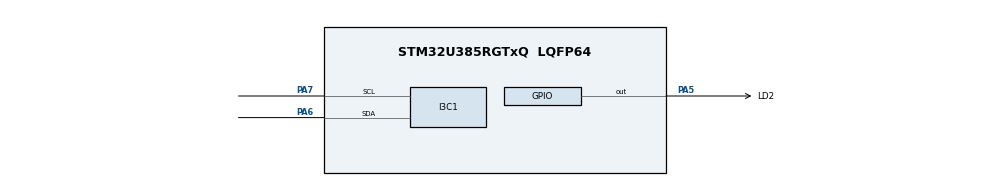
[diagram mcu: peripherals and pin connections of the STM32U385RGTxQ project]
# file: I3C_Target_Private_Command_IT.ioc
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CORTEX_M33_NS.userName=CORTEX_M33
I3C1.Identifier=0xC6
I3C1.MIPIIdentifier=DEVICE_ID
I3C1.Register1=0x0000005e
I3C1.hexBusAvailableDuration=0x5e
Mcu.Family=STM32U3
Mcu.Name=STM32U385RGTxQ
Mcu.Package=LQFP64
Mcu.UserConstants=DEVICE_ID,0x01
NVIC.I3C1_ER_IRQn=true\:0\:0\:false\:false\:true\:true\:true\:true
NVIC.I3C1_EV_IRQn=true\:0\:0\:false\:false\:true\:true\:true\:true
NVIC.PriorityGroup=NVIC_PRIORITYGROUP_4
PA5.GPIO_Label=LD2
PA5.Signal=GPIO_Output
PA6.Mode=Target
PA6.Signal=I3C1_SDA
PA7.Mode=Target
PA7.Signal=I3C1_SCL
ProjectManager.HeapSize=0x200
ProjectManager.StackSize=0x400
ProjectManager.TargetToolchain=EWARM V9.20
RCC.ADCFreq_Value=96000000
RCC.AHBFreq_Value=96000000
RCC.APB1Freq_Value=96000000
RCC.APB1TimFreq_Value=96000000
RCC.APB2Freq_Value=96000000
RCC.APB2TimFreq_Value=96000000
RCC.APB3Freq_Value=96000000
RCC.CortexFreq_Value=12000000
RCC.HCLKFreq_Value=96000000
RCC.HSE_VALUE=16000000
RCC.HSI48_VALUE=48000000
RCC.HSI_VALUE=16000000
RCC.LSE_VALUE=32768
RCC.LSIDIV_VALUE=32000
RCC.MSISDIV=RCC_MSI_DIV1
RCC.SYSCLKFreq_VALUE=96000000
RCC.USBFreq_Value=96000000
VP_ICACHE_VS_ICACHE.Mode=DirectMappedCache
VP_PWR_VS_DBSignals.Mode=DisableDeadBatterySignals
VP_PWR_VS_LPOM.Mode=PowerOptimisation
VP_PWR_VS_SECSignals.Mode=Security/Privilege
board=custom

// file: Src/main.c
/* USER CODE BEGIN Header */
/**
  ******************************************************************************
  * @file    I3C/I3C_Target_Private_Command_IT/Src/main.c
  * @author  MCD Application Team
  * @brief   This sample code shows how to use STM32U3xx I3C LL API as Target
  *          to receive and transmit a data buffer
  *          with a communication process based on Interrupt transfer.
  *          The communication is done using 2 Boards.
  ******************************************************************************
  * @attention
  *
  * Copyright (c) 2024 STMicroelectronics.
  * All rights reserved.
  *
  * This software is licensed under terms that can be found in the LICENSE file
  * in the root directory of this software component.
  * If no LICENSE file comes with this software, it is provided AS-IS.
  *
  ******************************************************************************
  */
/* USER CODE END Header */
#include "main.h"

/* USER CODE BEGIN PV */
/* Buffer used for transmission */
uint8_t aTxBuffer[] = " ****I3C_TwoBoards communication based on IT****  ****I3C_TwoBoards communication based on IT****  ****I3C_TwoBoards communication based on IT**** ";
/* Buffer used for reception */
uint8_t aRxBuffer[RXBUFFERSIZE];
/* Buffer used for reception */
__IO uint8_t ubNbRxData = 0;
/* Buffer used for transmission */
__IO uint8_t ubNbTxData = 0;
/* Completion status */
__IO uint8_t ubFrameComplete = 0;
/* USER CODE END PV */

void SystemClock_Config(void);
static void MX_GPIO_Init(void);
static void MX_I3C1_Init(void);
static void MX_ICACHE_Init(void);
/* USER CODE BEGIN PFP */
void LED_On(void);
void LED_Off(void);
void LED_Toggle(void);
void LED_Blinking(uint32_t Period);
void FlushBuffer8(uint8_t* pBuffer1, uint16_t BufferSize);
static uint16_t Buffercmp(uint8_t *pBuffer1, uint8_t *pBuffer2, uint16_t BufferLength);
/* USER CODE END PFP */

int main(void)
{

  /* MCU Configuration--------------------------------------------------------*/

  /* Reset of all peripherals, Initializes the Flash interface and the Systick. */

  /* System interrupt init*/
  NVIC_SetPriorityGrouping(NVIC_PRIORITYGROUP_4);

  /* SysTick_IRQn interrupt configuration */
  NVIC_SetPriority(SysTick_IRQn, NVIC_EncodePriority(NVIC_GetPriorityGrouping(),15, 0));

  /* Configure the system clock */
  SystemClock_Config();

  /* Initialize all configured peripherals */
  MX_GPIO_Init();
  MX_I3C1_Init();
  MX_ICACHE_Init();
  /* USER CODE BEGIN 2 */
  /* Set LD2 Off */
  LED_Off();
  /* Set Preload information */
  LL_I3C_ConfigTxPreload(I3C1, TXBUFFERSIZE);
  /* Wait end of Private transfer procedure */
  while(ubFrameComplete != 2);
  /*##- Compare the sent and received buffers ############################*/
  if (Buffercmp((uint8_t *)aTxBuffer, (uint8_t *)aRxBuffer, RXBUFFERSIZE))
  {
    /* Processing Error */
    Error_Handler();
  }
  else
  {
    /* LD2 On */
    LED_On();
  }
  /* USER CODE END 2 */

  /* Infinite loop */
  while (1)
  {

  }
}

void SystemClock_Config(void)
{
  /** Enable Epod Booster
  */
  LL_AHB1_GRP2_EnableClock(LL_AHB1_GRP2_PERIPH_PWR);
  LL_RCC_SetEPODBoosterClkSource(LL_RCC_EPODBOOSTCLKSRCE_MSIS);
  LL_RCC_SetEPODBoosterClkPrescaler(LL_RCC_EPODBOOSTCLKPRESCAL_1);
  LL_PWR_EnableEPODBooster();
  while(LL_PWR_IsActiveFlag_BOOST() != 1U)
  {
  }

  /** Configure the main internal regulator output voltage
  */
  LL_PWR_SetRegulVoltageScaling(LL_PWR_REGU_VOLTAGE_SCALE1);
  while(LL_PWR_GetRegulCurrentVOS() != LL_PWR_REGU_VOLTAGE_SCALE1)
  {
  }

  /** Set Flash latency before switching to MSIS
  */
  LL_FLASH_SetLatency(LL_FLASH_LATENCY_2);
  while(LL_FLASH_GetLatency() != LL_FLASH_LATENCY_2)
  {
  }

  /** Activate MSIS as source
  */
  LL_RCC_MSIS_SetClockSource(LL_RCC_MSIS_CLOCK_SOURCE_RC0);
  LL_RCC_MSIS_SetClockDivision(LL_RCC_MSIS_CLOCK_SOURCE_RC_DIV_1);
  LL_RCC_MSI_SetMSIxClockRange();
  LL_RCC_SetSysClkSource(LL_RCC_SYS_CLKSOURCE_MSIS);

  /** Wait till System clock is ready
  */
  while(LL_RCC_GetSysClkSource() != LL_RCC_SYS_CLKSOURCE_MSIS)
  {
  }

  LL_RCC_SetAHBPrescaler(LL_RCC_HCLK_SYSCLK_DIV_1);
  LL_RCC_SetAPB1Prescaler(LL_RCC_APB1_HCLK_DIV_1);
  LL_RCC_SetAPB2Prescaler(LL_RCC_APB2_HCLK_DIV_1);
  LL_RCC_SetAPB3Prescaler(LL_RCC_APB3_HCLK_DIV_1);

  LL_Init1msTick(96000000);

  LL_SetSystemCoreClock(96000000);
}

static void MX_I3C1_Init(void)
{

  LL_GPIO_InitTypeDef GPIO_InitStruct = {0};

  LL_RCC_SetI3CClockSource(LL_RCC_I3C1_CLKSOURCE_PCLK1);

  /* Peripheral clock enable */
  LL_APB1_GRP1_EnableClock(LL_APB1_GRP1_PERIPH_I3C1);

  LL_AHB2_GRP1_EnableClock(LL_AHB2_GRP1_PERIPH_GPIOA);
  /**I3C1 GPIO Configuration
  PA6   ------> I3C1_SDA
  PA7   ------> I3C1_SCL
  */
  GPIO_InitStruct.Pin = LL_GPIO_PIN_6|LL_GPIO_PIN_7;
  GPIO_InitStruct.Mode = LL_GPIO_MODE_ALTERNATE;
  GPIO_InitStruct.Speed = LL_GPIO_SPEED_FREQ_VERY_HIGH;
  GPIO_InitStruct.OutputType = LL_GPIO_OUTPUT_PUSHPULL;
  GPIO_InitStruct.Pull = LL_GPIO_PULL_NO;
  GPIO_InitStruct.Alternate = LL_GPIO_AF_6;
  LL_GPIO_Init(GPIOA, &GPIO_InitStruct);

  /* I3C1 interrupt Init */
  NVIC_SetPriority(I3C1_EV_IRQn, NVIC_EncodePriority(NVIC_GetPriorityGrouping(),0, 0));
  NVIC_EnableIRQ(I3C1_EV_IRQn);
  NVIC_SetPriority(I3C1_ER_IRQn, NVIC_EncodePriority(NVIC_GetPriorityGrouping(),0, 0));
  NVIC_EnableIRQ(I3C1_ER_IRQn);

  /** I3C Initialization
  */
  LL_I3C_SetMode(I3C1, LL_I3C_MODE_TARGET);
  LL_I3C_SetAvalTiming(I3C1, 0x0000005e);

  /** Configure FIFO
  */
  LL_I3C_SetRxFIFOThreshold(I3C1, LL_I3C_RXFIFO_THRESHOLD_1_4);
  LL_I3C_SetTxFIFOThreshold(I3C1, LL_I3C_TXFIFO_THRESHOLD_1_4);
  LL_I3C_DisableControlFIFO(I3C1);
  LL_I3C_DisableStatusFIFO(I3C1);

  /** Configure Target
  */
  LL_I3C_SetDeviceCharacteristics(I3C1, 0xC6);
  LL_I3C_SetMIPIInstanceID(I3C1, DEVICE_ID);
  LL_I3C_DisableControllerRoleReq(I3C1);
  LL_I3C_DisableHotJoin(I3C1);
  LL_I3C_DisableIBI(I3C1);
  LL_I3C_SetDeviceIBIPayload(I3C1, LL_I3C_IBI_NO_ADDITIONAL_DATA);
  LL_I3C_ConfigNbIBIAddData(I3C1, LL_I3C_PAYLOAD_1_BYTE);
  LL_I3C_SetMaxReadLength(I3C1, 0);
  LL_I3C_SetMaxWriteLength(I3C1, 0);
  LL_I3C_SetDeviceCapabilityOnBus(I3C1, LL_I3C_DEVICE_ROLE_AS_TARGET);
  LL_I3C_SetGrpAddrHandoffSupport(I3C1, LL_I3C_HANDOFF_GRP_ADDR_NOT_SUPPORTED);
  LL_I3C_SetDataTurnAroundTime(I3C1, LL_I3C_TURNAROUND_TIME_TSCO_LESS_12NS);
  LL_I3C_SetMiddleByteTurnAround(I3C1, 0);
  LL_I3C_SetDataSpeedLimitation(I3C1, LL_I3C_NO_DATA_SPEED_LIMITATION);
  LL_I3C_SetMaxDataSpeedFormat(I3C1, LL_I3C_GETMXDS_FORMAT_1);
  LL_I3C_SetHandoffActivityState(I3C1, LL_I3C_HANDOFF_ACTIVITY_STATE_0);
  LL_I3C_SetControllerHandoffDelayed(I3C1, LL_I3C_HANDOFF_NOT_DELAYED);
  LL_I3C_SetPendingReadMDB(I3C1, LL_I3C_MDB_NO_PENDING_READ_NOTIFICATION);

  /** Enable the selected I3C peripheral
  */
  LL_I3C_Enable(I3C1);
  /* USER CODE BEGIN I3C1_Init 2 */
  LL_I3C_EnableIT_DAUPD(I3C1);
  LL_I3C_EnableIT_FC(I3C1);
  LL_I3C_EnableIT_RXFNE(I3C1);
  LL_I3C_EnableIT_TXFNF(I3C1);
  LL_I3C_EnableIT_ERR(I3C1);
  /* USER CODE END I3C1_Init 2 */

}

static void MX_ICACHE_Init(void)
{

  /** Enable instruction cache in 1-way (direct mapped cache)
  */
  LL_ICACHE_SetMode(LL_ICACHE_1WAY);
  LL_ICACHE_Enable();

}

static void MX_GPIO_Init(void)
{
  LL_GPIO_InitTypeDef GPIO_InitStruct = {0};

  /* GPIO Ports Clock Enable */
  LL_AHB2_GRP1_EnableClock(LL_AHB2_GRP1_PERIPH_GPIOA);

  /**/
  LL_GPIO_ResetOutputPin(LD2_GPIO_Port, LD2_Pin);

  /**/
  GPIO_InitStruct.Pin = LD2_Pin;
  GPIO_InitStruct.Mode = LL_GPIO_MODE_OUTPUT;
  GPIO_InitStruct.Speed = LL_GPIO_SPEED_FREQ_LOW;
  GPIO_InitStruct.OutputType = LL_GPIO_OUTPUT_PUSHPULL;
  GPIO_InitStruct.Pull = LL_GPIO_PULL_NO;
  LL_GPIO_Init(LD2_GPIO_Port, &GPIO_InitStruct);

}

/* USER CODE BEGIN 4 */
/**
  * @brief  Flush 8-bit buffer.
  * @param  pBuffer1: pointer to the buffer to be flushed.
  * @param  BufferSize: Size of Buffer.
  * @retval None
  */
void FlushBuffer8(uint8_t* pBuffer1, uint16_t BufferSize)
{
  uint8_t Index = 0;
  for (Index = 0; Index < BufferSize; Index++)
  {
    pBuffer1[Index] = 0;
  }
}
/**
  * @brief  Turn-on LD2.
  * @param  None
  * @retval None
  */
void LED_On(void)
{
  /* Turn LD2 on */
  LL_GPIO_SetOutputPin(LD2_GPIO_Port, LD2_Pin);
}
/**
  * @brief  Turn-off LD2.
  * @param  None
  * @retval None
  */
void LED_Off(void)
{
  /* Turn LD2 off */
  LL_GPIO_ResetOutputPin(LD2_GPIO_Port, LD2_Pin);
}
/**
  * @brief  Toggle LD2.
  * @param  None
  * @retval None
  */
void LED_Toggle(void)
{
  /* Toggle LD2 on */
  LL_GPIO_TogglePin(LD2_GPIO_Port, LD2_Pin);
}
/**
  * @brief  Set LD2 to Blinking mode for an infinite loop (toggle period based on value provided as input parameter).
  * @param  Period : Period of time (in ms) between each toggling of LED
  *   This parameter can be user defined values. Pre-defined values used in that example are :
  *     @arg LED_BLINK_FAST : Fast Blinking
  *     @arg LED_BLINK_SLOW : Slow Blinking
  *     @arg LED_BLINK_ERROR : Error specific Blinking
  * @retval None
  */
void LED_Blinking(uint32_t Period)
{
  /* Turn LD2 on */
  LED_On();
  /* Toggle IO in an infinite loop */
  while (1)
  {
    LED_Toggle();
    LL_mDelay(Period);
  }
}
/**
  * @brief  Compares two buffers.
  * @param  pBuffer1, pBuffer2: buffers to be compared.
  * @param  BufferLength: buffer's length
  * @retval 0  : pBuffer1 identical to pBuffer2
  *         >0 : pBuffer1 differs from pBuffer2
  */
static uint16_t Buffercmp(uint8_t *pBuffer1, uint8_t *pBuffer2, uint16_t BufferLength)
{
  while (BufferLength--)
  {
    if ((*pBuffer1) != *pBuffer2)
    {
      return BufferLength;
    }
    pBuffer1++;
    pBuffer2++;
  }
  return 0;
}
/******************************************************************************/
/*   IRQ HANDLER TREATMENT Functions                                          */
/******************************************************************************/
/**
  * @brief  Target Event treatment callback.
  * @param  targetPayload Parameter indicates the target payload.
  * @retval None
  */
void Target_Event_Treatment_Callback(void)
{
  /* Check Dynamic Address update flag in EVR register */
  if (LL_I3C_IsActiveFlag_DAUPD(I3C1))
  {
    /* Clear Dynamic Address update flag */
    LL_I3C_ClearFlag_DAUPD(I3C1);
    /* Toggle LD2: Dynamic address received */
    LED_Toggle();
  }
}
/**
  * @brief  Target Complete callback.
  * @param  None
  * @retval None
  */
void Target_Complete_Callback(void)
{
  /* Update Completion status */
  ubFrameComplete++;
  /* Toggle LD2: Transfer in Transmission process is correct */
  LED_Toggle();
}
/**
  * @brief  Target Receive callback.
  * @param  None
  * @retval None
  */
void Target_Reception_Callback(void)
{
  while (LL_I3C_IsActiveFlag_RXFNE(I3C1))
  {
    aRxBuffer[ubNbRxData++] = LL_I3C_ReceiveData8(I3C1);
  }
}
/**
  * @brief  Target Transmit callback.
  * @param  None
  * @retval None
  */
void Target_Transmit_Callback(void)
{
  while (LL_I3C_IsActiveFlag_TXFNF(I3C1) && (ubNbTxData < TXBUFFERSIZE))
  {
    /* Write Tx buffer data to transmit register */
    LL_I3C_TransmitData8(I3C1, aTxBuffer[ubNbTxData++]);
  }
}
/* USER CODE END 4 */

void Error_Handler(void)
{
  /* USER CODE BEGIN Error_Handler_Debug */
  /* User can add his own implementation to report the LL error return state */
  while (1)
  {
    /* Unexpected event : Set LD2 to Blinking mode to indicate error occurs */
    LED_Blinking(LED_BLINK_ERROR);
  }
  /* USER CODE END Error_Handler_Debug */
}
